# InterruptCollectorIfc: IP-XACT component
VLNV eccelerators.com:interface:InterruptCollectorIfc:0.0.1

## Address spaces and blocks
InterruptCollectorBlk.InterruptMaskReg: base 0, range 4, width 8
InterruptCollectorBlk.InterruptRequestReg: base 4, range 4, width 8
InterruptCollectorBlk.InterruptServiceReg: base 8, range 4, width 8

## Registers
Registers are 32-bit, read-write, reset 0x0 unless marked. A register's access mark holds for its fields unless they carry their own. Offsets are from the block's base; lines under a group give offsets from that group; [hi:lo] are bit positions; {n}, {i} and the like mark numbered series; 'fields as' and 'values as' point back to an identical list; <NAME> marks a mode.

## InterruptCollectorBlk.InterruptMaskReg
Base 0x00000000
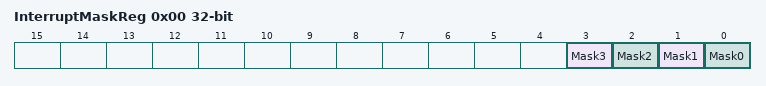
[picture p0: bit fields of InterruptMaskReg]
0x00 InterruptMaskReg reset not defined — Interrupt Mask Register
  [3] Mask3
    0=Mask3_InterruptDisabled (Interrupt is not forwarded to CPU(s).); 8=Mask3_InterruptEnabled (Interrupt is forwarded to CPU(s).)
  [2] Mask2
    0=Mask2_InterruptDisabled (Interrupt is not forwarded to CPU(s).); 4=Mask2_InterruptEnabled (Interrupt is forwarded to CPU(s).)
  [1] Mask1
    0=Mask1_InterruptDisabled (Interrupt is not forwarded to CPU(s).); 2=Mask1_InterruptEnabled (Interrupt is forwarded to CPU(s).)
  [0] Mask0
    0=Mask0_InterruptDisabled (Interrupt is not forwarded to CPU(s).); 1=Mask0_InterruptEnabled (Interrupt is forwarded to CPU(s).)

## InterruptCollectorBlk.InterruptRequestReg
Base 0x00000004
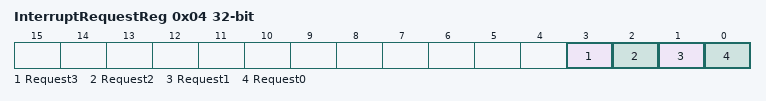
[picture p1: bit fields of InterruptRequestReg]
0x04 InterruptRequestReg (reset mask 0x1) — Interrupt Request Register
  [3] Request3
    0=Request3_NotPending (An Interrupt is not pending.); 8=Request3_Pending (An Interrupt is pending.); 0=Request3_NotConfirmed; 8=Request3_Confirmed (SW confirms that a respective interrupt service routine has been entered. The value isn't stored, thus there is no need to reset it to '0' again. Solely the write action is sufficient.)
  [2] Request2
    0=Request2_NotPending (An Interrupt is not pending.); 4=Request2_Pending (An Interrupt is pending.); 0=Request2_NotConfirmed; 4=Request2_Confirmed (SW confirms that a respective interrupt service routine has been entered. The value isn't stored, thus there is no need to reset it to '0' again. Solely the write action is sufficient.)
  [1] Request1
    0=Request1_NotPending (An Interrupt is not pending.); 2=Request1_Pending (An Interrupt is pending.); 0=Request1_NotConfirmed; 2=Request1_Confirmed (SW confirms that a respective interrupt service routine has been entered. The value isn't stored, thus there is no need to reset it to '0' again. Solely the write action is sufficient.)
  [0] Request0
    0=Request0_NotPending (An Interrupt is not pending.); 1=Request0_Pending (An Interrupt is pending.); 0=Request0_NotConfirmed; 1=Request0_Confirmed (SW confirms that a respective interrupt service routine has been entered. The value isn't stored, thus there is no need to reset it to '0' again. Solely the write action is sufficient.)

## InterruptCollectorBlk.InterruptServiceReg
Base 0x00000008
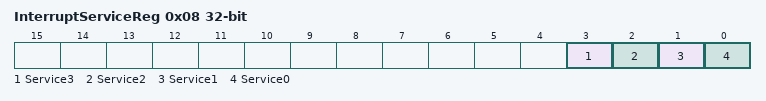
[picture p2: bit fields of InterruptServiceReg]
0x08 InterruptServiceReg (reset mask 0x1) — Interrupt Service Register
  [3] Service3
    0=Service3_Ended (The Interrupt service has ended.); 8=Service3_InProcess (The Interrupt is in service.); 0=Service3_NotConfirmed; 8=Service3_Confirmed (SW confirms that a respective interrupt service routine has been processed completely. The value isn't stored, thus there is no need to reset it to '0' again. Solely the write action is sufficient.)
  [2] Service2
    0=Service2_Ended (The Interrupt service has ended.); 4=Service2_InProcess (The Interrupt is in service.); 0=Service2_NotConfirmed; 4=Service2_Confirmed (SW confirms that a respective interrupt service routine has been processed completely. The value isn't stored, thus there is no need to reset it to '0' again. Solely the write action is sufficient.)
  [1] Service1
    0=Service1_Ended (The Interrupt service has ended.); 2=Service1_InProcess (The Interrupt is in service.); 0=Service1_NotConfirmed; 2=Service1_Confirmed (SW confirms that a respective interrupt service routine has been processed completely. The value isn't stored, thus there is no need to reset it to '0' again. Solely the write action is sufficient.)
  [0] Service0
    0=Service0_Ended (The Interrupt service has ended.); 1=Service0_InProcess (The Interrupt is in service.); 0=Service0_NotConfirmed; 1=Service0_Confirmed (SW confirms that a respective interrupt service routine has been processed completely. The value isn't stored, thus there is no need to reset it to '0' again. Solely the write action is sufficient.)
